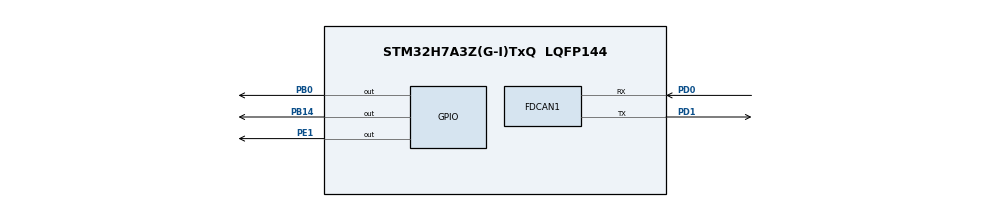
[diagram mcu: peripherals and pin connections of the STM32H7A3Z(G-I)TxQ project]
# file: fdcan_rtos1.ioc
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FDCAN1.AutoRetransmission=ENABLE
FDCAN1.DataSyncJumpWidth=4
FDCAN1.DataTimeSeg1=5
FDCAN1.DataTimeSeg2=4
FDCAN1.FrameFormat=FDCAN_FRAME_FD_NO_BRS
FDCAN1.NominalTimeSeg1=5
FDCAN1.RxBuffersNbr=1
FDCAN1.RxFifo0ElmtsNbr=1
FDCAN1.StdFiltersNbr=1
FREERTOS.Tasks01=defaultTask,24,128,StartDefaultTask,Default,NULL,Dynamic,NULL,NULL;myTask02,8,128,StartTask02,Default,NULL,Dynamic,NULL,NULL;myTask03,8,128,StartTask03,Default,NULL,Dynamic,NULL,NULL
FREERTOS.configUSE_NEWLIB_REENTRANT=1
Mcu.Family=STM32H7
Mcu.Name=STM32H7A3Z(G-I)TxQ
Mcu.Package=LQFP144
NVIC.FDCAN1_IT0_IRQn=true\:5\:0\:false\:false\:true\:true\:true\:true
NVIC.PriorityGroup=NVIC_PRIORITYGROUP_4
NVIC.TIM4_IRQn=true\:15\:0\:false\:false\:true\:false\:false\:true
NVIC.TimeBase=TIM4_IRQn
NVIC.TimeBaseIP=TIM4
PB0.Signal=GPIO_Output
PB14.Signal=GPIO_Output
PD0.Mode=FDCAN_Activate
PD0.Signal=FDCAN1_RX
PD1.Mode=FDCAN_Activate
PD1.Signal=FDCAN1_TX
PE1.Signal=GPIO_Output
PH0-OSC_IN.Mode=HSE-External-Oscillator
PH0-OSC_IN.Signal=RCC_OSC_IN
PH1-OSC_OUT.Mode=HSE-External-Oscillator
PH1-OSC_OUT.Signal=RCC_OSC_OUT
ProjectManager.HeapSize=0x200
ProjectManager.StackSize=0x400
ProjectManager.TargetToolchain=STM32CubeIDE
RCC.ADCFreq_Value=129000000
RCC.APB1Freq_Value=32000000
RCC.APB2Freq_Value=32000000
RCC.APB3Freq_Value=32000000
RCC.APB4Freq_Value=32000000
RCC.CDPPRE=RCC_APB3_DIV2
RCC.CDPPRE1=RCC_APB1_DIV2
RCC.CDPPRE2=RCC_APB2_DIV2
RCC.CortexFreq_Value=64000000
RCC.DIVM1=4
RCC.DIVN1=8
RCC.DIVQ1=32
RCC.HCLKFreq_Value=64000000
RCC.PLLFRACN=0
RCC.SRDPPRE=RCC_APB4_DIV2
RCC.SYSCLKFreq_VALUE=64000000
RCC.USBFreq_Value=4000000
VP_FREERTOS_VS_CMSIS_V2.Mode=CMSIS_V2
VP_SYS_VS_tim4.Mode=TIM4
board=custom

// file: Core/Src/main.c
/* USER CODE BEGIN Header */
/**
  ******************************************************************************
  * @file           : main.c
  * @brief          : Main program body
  ******************************************************************************
  * @attention
  *
  * Copyright (c) 2023 STMicroelectronics.
  * All rights reserved.
  *
  * This software is licensed under terms that can be found in the LICENSE file
  * in the root directory of this software component.
  * If no LICENSE file comes with this software, it is provided AS-IS.
  *
  ******************************************************************************
  */
/* USER CODE END Header */
#include "main.h"
#include "cmsis_os.h"
#include "fdcan.h"
#include "gpio.h"

/* USER CODE BEGIN Includes */
#include <stdio.h>
/* USER CODE END Includes */

/* USER CODE BEGIN PV */
FDCAN_FilterTypeDef sFilterConfig;
   FDCAN_TxHeaderTypeDef TxHeader;
   FDCAN_RxHeaderTypeDef RxHeader;
   uint8_t TxData_Node3_To_Node1[8];
   uint8_t TxData_Node3_To_Node2[8];
   uint8_t RxData_From_Node2[8];
   uint8_t RxData_From_Node1[8];
/* USER CODE END PV */

void SystemClock_Config(void);
void MX_FREERTOS_Init(void);

/* USER CODE BEGIN 0 */
void HAL_FDCAN_RxFifo0Callback(FDCAN_HandleTypeDef *hfdcan, uint32_t RxFifo0ITs)
{
//    printf("%s\r\n",);

//    HAL_Delay (1000);
   if(FDCAN1 == hfdcan->Instance){
  if((RxFifo0ITs & FDCAN_IT_RX_FIFO0_NEW_MESSAGE) != RESET)
  {

//       HAL_Delay (1000);
    /* Retreive Rx messages from RX FIFO0 */
     //?  기서?   �???? ? RX FIFO0?   ?  ?   ?  �???? ?? RxHeader ??????? 복사?   ??????? ?  ?  ?   ??????? RxData 배열 ??????? 복사?  ?  ?  .
    if (HAL_FDCAN_GetRxMessage(hfdcan, FDCAN_RX_FIFO0, &RxHeader, RxData_From_Node2) != HAL_OK)
    {
    /* Reception Error */
    Error_Handler();
    }
   }
   }
}
/* USER CODE END 0 */

int main(void)
{

  /* MCU Configuration--------------------------------------------------------*/

  /* Reset of all peripherals, Initializes the Flash interface and the Systick. */
  HAL_Init();

  /* Configure the system clock */
  SystemClock_Config();

  /* Initialize all configured peripherals */
  MX_GPIO_Init();
  MX_FDCAN1_Init();

  /* Init scheduler */
  osKernelInitialize();  /* Call init function for freertos objects (in freertos.c) */
  MX_FREERTOS_Init();
  /* Start scheduler */
  //osKernelStart();

  /* We should never get here as control is now taken by the scheduler */
  /* Infinite loop */
  /* USER CODE BEGIN WHILE */
  while (1)
  {

//		sprintf ((char *)TxData_Node3_To_Node2,"1234");
//		 if (HAL_FDCAN_AddMessageToTxFifoQ(&hfdcan1, &TxHeader, TxData_Node3_To_Node2)!= HAL_OK)
//		                           {
//		                              Error_Handler();
//		                           }
//
//		HAL_Delay(10);
    /* USER CODE END WHILE */

  }
}

void SystemClock_Config(void)
{
  RCC_OscInitTypeDef RCC_OscInitStruct = {0};
  RCC_ClkInitTypeDef RCC_ClkInitStruct = {0};

  /** Supply configuration update enable
  */
  HAL_PWREx_ConfigSupply(PWR_DIRECT_SMPS_SUPPLY);
  /** Configure the main internal regulator output voltage
  */
  __HAL_PWR_VOLTAGESCALING_CONFIG(PWR_REGULATOR_VOLTAGE_SCALE3);

  while(!__HAL_PWR_GET_FLAG(PWR_FLAG_VOSRDY)) {}
  /** Initializes the RCC Oscillators according to the specified parameters
  * in the RCC_OscInitTypeDef structure.
  */
  RCC_OscInitStruct.OscillatorType = RCC_OSCILLATORTYPE_HSI;
  RCC_OscInitStruct.HSIState = RCC_HSI_DIV1;
  RCC_OscInitStruct.HSICalibrationValue = RCC_HSICALIBRATION_DEFAULT;
  RCC_OscInitStruct.PLL.PLLState = RCC_PLL_ON;
  RCC_OscInitStruct.PLL.PLLSource = RCC_PLLSOURCE_HSI;
  RCC_OscInitStruct.PLL.PLLM = 4;
  RCC_OscInitStruct.PLL.PLLN = 8;
  RCC_OscInitStruct.PLL.PLLP = 2;
  RCC_OscInitStruct.PLL.PLLQ = 32;
  RCC_OscInitStruct.PLL.PLLR = 2;
  RCC_OscInitStruct.PLL.PLLRGE = RCC_PLL1VCIRANGE_3;
  RCC_OscInitStruct.PLL.PLLVCOSEL = RCC_PLL1VCOWIDE;
  RCC_OscInitStruct.PLL.PLLFRACN = 0;
  if (HAL_RCC_OscConfig(&RCC_OscInitStruct) != HAL_OK)
  {
    Error_Handler();
  }
  /** Initializes the CPU, AHB and APB buses clocks
  */
  RCC_ClkInitStruct.ClockType = RCC_CLOCKTYPE_HCLK|RCC_CLOCKTYPE_SYSCLK
                              |RCC_CLOCKTYPE_PCLK1|RCC_CLOCKTYPE_PCLK2
                              |RCC_CLOCKTYPE_D3PCLK1|RCC_CLOCKTYPE_D1PCLK1;
  RCC_ClkInitStruct.SYSCLKSource = RCC_SYSCLKSOURCE_HSI;
  RCC_ClkInitStruct.SYSCLKDivider = RCC_SYSCLK_DIV1;
  RCC_ClkInitStruct.AHBCLKDivider = RCC_HCLK_DIV1;
  RCC_ClkInitStruct.APB3CLKDivider = RCC_APB3_DIV2;
  RCC_ClkInitStruct.APB1CLKDivider = RCC_APB1_DIV2;
  RCC_ClkInitStruct.APB2CLKDivider = RCC_APB2_DIV2;
  RCC_ClkInitStruct.APB4CLKDivider = RCC_APB4_DIV2;

  if (HAL_RCC_ClockConfig(&RCC_ClkInitStruct, FLASH_LATENCY_2) != HAL_OK)
  {
    Error_Handler();
  }
}

void HAL_TIM_PeriodElapsedCallback(TIM_HandleTypeDef *htim)
{
  if (htim->Instance == TIM4) {
    HAL_IncTick();
  }
}

void Error_Handler(void)
{
  __disable_irq();
  while (1)
  {
  }
}
